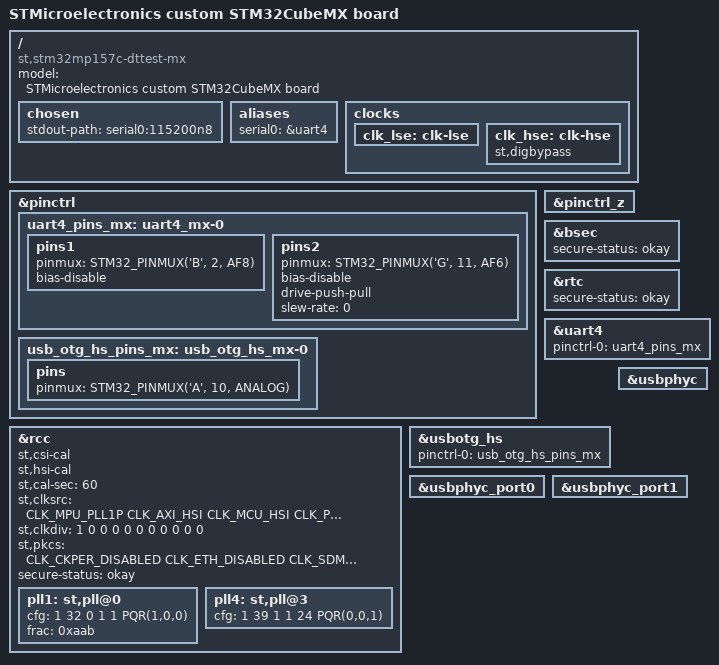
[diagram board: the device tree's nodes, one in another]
/* SPDX-License-Identifier: (GPL-2.0+ OR BSD-3-Clause) */
/*
 * Copyright (C) STMicroelectronics 2020 - All Rights Reserved
 * Author: STM32CubeMX code generation for STMicroelectronics.
 */

/* For more information on Device Tree configuration, please refer to
 * https://wiki.st.com/stm32mpu/wiki/Category:Device_tree_configuration
 */

/dts-v1/;
#include <dt-bindings/clock/stm32mp1-clksrc.h>

#include "stm32mp157c.dtsi"
#include "stm32mp157caa-pinctrl.dtsi"
/* !!! log : Warning - DDR not configured: unknown DDR dtsi  !!! */
/*#include "???-ddr.dtsi"*/
#include "stm32mp157c-security.dtsi"

/* USER CODE BEGIN includes */
/* USER CODE END includes */

/ {
	model = "STMicroelectronics custom STM32CubeMX board";
	compatible = "st,stm32mp157c-dttest-mx", "st,stm32mp157";

	/* USER CODE BEGIN root */
	chosen {
		stdout-path = "serial0:115200n8";
	};

	aliases {
		serial0 = &uart4;
	};
	/* USER CODE END root */

	clocks {
		/* USER CODE BEGIN clocks */
		/* USER CODE END clocks */

		clk_lse: clk-lse {

			/* USER CODE BEGIN clk_lse */
			/* USER CODE END clk_lse */
		};

		clk_hse: clk-hse {
			st,digbypass;

			/* USER CODE BEGIN clk_hse */
			/* USER CODE END clk_hse */
		};
	};

}; /*root*/

&pinctrl {
	uart4_pins_mx: uart4_mx-0 {
		pins1 {
			pinmux = <STM32_PINMUX('B', 2, AF8)>; /* UART4_RX */
			bias-disable;
		};
		pins2 {
			pinmux = <STM32_PINMUX('G', 11, AF6)>; /* UART4_TX */
			bias-disable;
			drive-push-pull;
			slew-rate = <0>;
		};
	};

	usb_otg_hs_pins_mx: usb_otg_hs_mx-0 {
		pins {
			pinmux = <STM32_PINMUX('A', 10, ANALOG)>; /* USB_OTG_HS_ID */
		};
	};

	/* USER CODE BEGIN pinctrl */
	/* USER CODE END pinctrl */
};

&pinctrl_z {
	/* USER CODE BEGIN pinctrl_z */
	/* USER CODE END pinctrl_z */
};

&rcc {
	st,csi-cal;
	st,hsi-cal;
	st,cal-sec = <60>;
	st,clksrc = <
		CLK_MPU_PLL1P
		CLK_AXI_HSI
		CLK_MCU_HSI
		CLK_PLL12_HSE
		CLK_PLL3_HSE
		CLK_PLL4_HSE
		CLK_RTC_LSI
		CLK_MCO1_DISABLED
		CLK_MCO2_DISABLED
	>;
	st,clkdiv = <
		1 		/*MPU*/
		0 		/*AXI*/
		0 		/*MCU*/
		0 		/*APB1*/
		0 		/*APB2*/
		0 		/*APB3*/
		0 		/*APB4*/
		0 		/*APB5*/
		0 		/*RTC*/
		0 		/*MCO1*/
		0 		/*MCO2*/
	>;
	st,pkcs = <
		CLK_CKPER_DISABLED
		CLK_ETH_DISABLED
		CLK_SDMMC12_DISABLED
		CLK_STGEN_HSI
		CLK_USBPHY_PLL4R
		CLK_SPI2S1_DISABLED
		CLK_SPI2S23_DISABLED
		CLK_SPI45_DISABLED
		CLK_SPI6_DISABLED
		CLK_I2C46_DISABLED
		CLK_SDMMC3_DISABLED
		CLK_USBO_PLL4R
		CLK_ADC_DISABLED
		CLK_CEC_DISABLED
		CLK_I2C12_DISABLED
		CLK_I2C35_DISABLED
		CLK_UART1_DISABLED
		CLK_UART24_PCLK1
		CLK_UART35_DISABLED
		CLK_UART6_DISABLED
		CLK_UART78_DISABLED
		CLK_SPDIF_DISABLED
		CLK_SAI1_DISABLED
		CLK_SAI2_DISABLED
		CLK_SAI3_DISABLED
		CLK_SAI4_DISABLED
		CLK_LPTIM1_DISABLED
		CLK_LPTIM23_DISABLED
		CLK_LPTIM45_DISABLED
	>;
	pll1:st,pll@0 {
		cfg = < 1 32 0 1 1 PQR(1,0,0) >;
		frac = < 0xaab>;
	};
	pll4:st,pll@3 {
		cfg = < 1 39 1 1 24 PQR(0,0,1) >;
	};
};

&bsec{
	status = "okay";
	secure-status = "okay";

	/* USER CODE BEGIN bsec */
	/* USER CODE END bsec */
};

&rcc{
	status = "okay";
	secure-status = "okay";

	/* USER CODE BEGIN rcc */
	/* USER CODE END rcc */
};

&rtc{
	status = "okay";
	secure-status = "okay";

	/* USER CODE BEGIN rtc */
	/* USER CODE END rtc */
};

&uart4{
	pinctrl-names = "default";
	pinctrl-0 = <&uart4_pins_mx>;
	status = "okay";

	/* USER CODE BEGIN uart4 */
	/* USER CODE END uart4 */
};

&usbotg_hs{
	pinctrl-names = "default";
	pinctrl-0 = <&usb_otg_hs_pins_mx>;
	status = "okay";

	/* USER CODE BEGIN usbotg_hs */
	/* USER CODE END usbotg_hs */
};

&usbphyc{
	status = "okay";

	/* USER CODE BEGIN usbphyc */
	/* USER CODE END usbphyc */
};

&usbphyc_port0{
	status = "okay";

	/* USER CODE BEGIN usbphyc_port0 */
	/* USER CODE END usbphyc_port0 */
};

&usbphyc_port1{
	status = "okay";

	/* USER CODE BEGIN usbphyc_port1 */
	/* USER CODE END usbphyc_port1 */
};

/* USER CODE BEGIN addons */
/* USER CODE END addons */

